# LCM32F039 register map
File version: 1.0
CPU: CM0 r1p0, little endian, MPU, no FPU, 3 interrupt priority bits
Registers are 32-bit, read-write, reset 0x0 unless marked. A register's access mark holds for its fields unless they carry their own. Offsets are from the block's base; [hi:lo] are bit positions; {n}, {i} and the like mark numbered series; 'fields as' and 'values as' point back to an identical list.

## DMAC — DMA control moudle
Base 0x48004000
{0x0+0x58*i} SAR{i} (i=0..3) — Channel {i} Source Address Register
  [31:0] SAR — Current Source Address of DMA transfer
{0x8+0x58*i} DAR{i} (i=0..3) — Channel {i} Destination Address Register
  [31:0] DAR — Current Destination address of DMA transfer
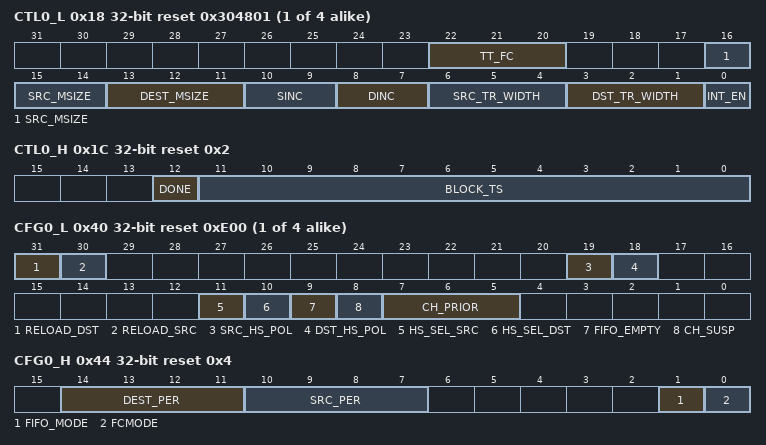
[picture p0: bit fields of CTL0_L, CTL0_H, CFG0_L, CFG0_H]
{0x18+0x58*i} CTL{i}_L reset 0x304801 (i=0..3) — Channel {i} Control Register low
  [22:20] TT_FC — Transport type and flow control
  [16:14] SRC_MSIZE — Source Burst transaction transmission length
  [13:11] DEST_MSIZE — Destination Burst Transaction Length
  [10:9] SINC — Source Address Increment
  [8:7] DINC — Destination Address Increment.
  [6:4] SRC_TR_WIDTH — Source Transfer Width
  [3:1] DST_TR_WIDTH — Destination Transfer Width
  [0] INT_EN — Interrupt Enable Bit
0x1C CTL0_H reset 0x2 — Channel 0 Source Status Register high
  [12] DONE — Done bit
  [11:0] BLOCK_TS — Block Transfer Size
{0x40+0x58*i} CFG{i}_L reset 0xE00 (i=0..3) — Channel {i} Configuration Register (low)
  [31] RELOAD_DST — Automatic Destination Reload.
  [30] RELOAD_SRC — Automatic Source Reload.
  [19] SRC_HS_POL — Source Handshaking Interface Polarity.
  [18] DST_HS_POL — Destination Handshaking Interface Polarity.
  [11] HS_SEL_SRC — Source Software or Hardware Handshaking Select.
  [10] HS_SEL_DST — Destination Software or Hardware Handshaking Select.
  [9] FIFO_EMPTY ro — Indicates if there is data left in the channel FIFO
  [8] CH_SUSP — Channel Suspend.
  [7:5] CH_PRIOR — Channel priority
0x44 CFG0_H reset 0x4 — Channel 0 Configuration Register (high)
  [14:11] DEST_PER — Assigns a hardware handshaking interface
  [10:7] SRC_PER — Assigns a hardware handshaking interface
  [1] FIFO_MODE — FIFO Mode Select.
  [0] FCMODE — Flow Control Mode
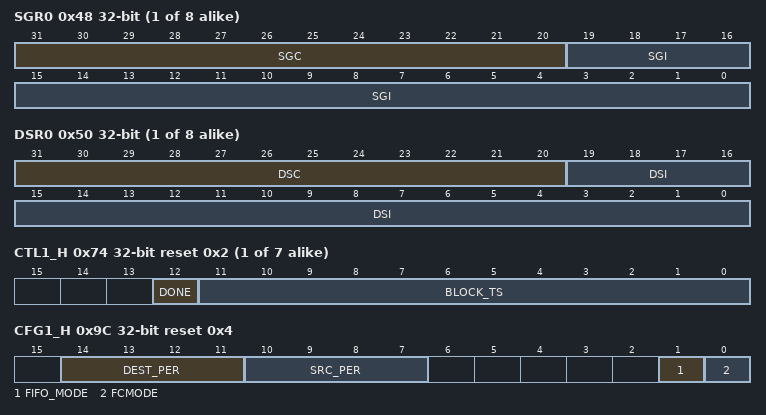
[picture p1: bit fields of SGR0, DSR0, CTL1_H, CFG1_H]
{0x48+0x58*i} SGR{i} (i=0..7) — Channel {i} Source Gather Register
  [31:20] SGC — Source gather count.
  [19:0] SGI — Source gather interval.
{0x50+0x58*i} DSR{i} (i=0..7) — Channel {i} Destination Scatter Register
  [31:20] DSC — Destination scatter count.
  [19:0] DSI — Destination scatter interval.
{0x1C+0x58*i} CTL{i}_H reset 0x2 (i=1..7) — Channel {i} Control Register high
  [12] DONE — Done bit
  [11:0] BLOCK_TS — Block Transfer Size
0x9C CFG1_H reset 0x4 — Channel 1 Configuration Register (high)
  fields as CFG0_H
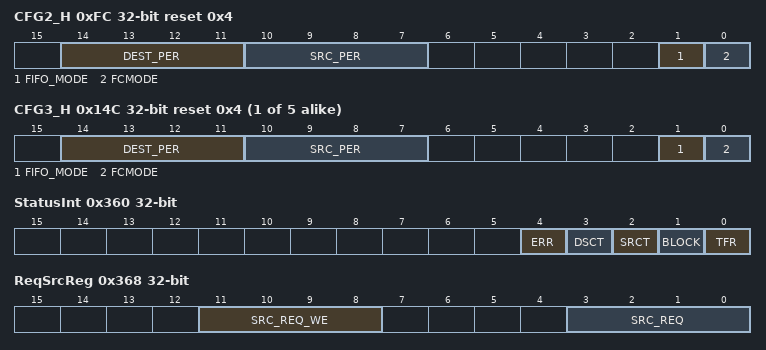
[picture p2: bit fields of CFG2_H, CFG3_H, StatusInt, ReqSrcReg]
0xFC CFG2_H reset 0x4 — Channel 2 Configuration Register (high)
  fields as CFG0_H
{0x44+0x58*i} CFG{i}_H reset 0x4 (i=3..7) — Channel {i} Configuration Register (high)
  fields as CFG0_H
0x2C0 RawTfr
  [3:0] RAWTr — Raw interrupt status
0x2C8 RawBlock
  [3:0] RAWTr — Raw interrupt status
0x2D0 RawSrcTran
  [3:0] RAWTr — Raw interrupt status
0x2D8 RawDstTran
  [3:0] RAWTr — Raw interrupt status
0x2E0 RawErr ro
  [3:0] RAWTr — Raw interrupt status
0x2E8 StatusTfr ro
  [3:0] StatusTfr — Interrupt status.
0x2F0 StatusBlock ro
  [3:0] StatusTfr — Interrupt status.
0x2F8 StatusSrcTran ro
  [3:0] StatusTfr — Interrupt status.
0x300 StatusDstTran ro
  [3:0] StatusTfr — Interrupt status.
0x308 StatusErr ro
  [3:0] StatusTfr — Interrupt status.
0x310 MaskTfr — Interrupt Mask Registers
  [15:8] INT_MASK_TFR_WE — Interrupt Mask Write Enable
0x318 MaskBlock — Interrupt Mask Registers
  [15:8] INT_MASK_TFR_WE — Interrupt Mask Write Enable
0x320 MaskSrcTran — Interrupt Mask Registers
  [15:8] INT_MASK_TFR_WE — Interrupt Mask Write Enable
0x328 MaskDstTran — Interrupt Mask Registers
  [15:8] INT_MASK_TFR_WE — Interrupt Mask Write Enable
0x330 MaskErr — Interrupt Mask Registers
  [15:8] INT_MASK_TFR_WE — Interrupt Mask Write Enable
0x338 ClearTfr wo — Interrupt Clear Registers
  [3:0] ClearTfr — Interrupt clear
0x340 ClearBlock wo — Interrupt Clear Registers
  [3:0] ClearTfr — Interrupt clear
0x348 ClearSrcTran wo — Interrupt Clear Registers
  [3:0] ClearTfr — Interrupt clear
0x350 ClearDstTran wo — Interrupt Clear Registers
  [3:0] ClearTfr — Interrupt clear
0x358 ClearErr wo — Interrupt Clear Registers
  [3:0] ClearTfr — Interrupt clear
0x360 StatusInt ro — Combined Interrupt Status Register
  [4] ERR — OR of the contents of StatusErr register.
  [3] DSCT — OR of the contents of StatusDst register.
  [2] SRCT — OR of the contents of StatusSrcTran register
  [1] BLOCK — OR of the contents of StatusBlock register.
  [0] TFR — OR of the contents of StatusTfr register
0x368 ReqSrcReg — Source Software Transaction Request Register
  [11:8] SRC_REQ_WE — Source request write enable
  [3:0] SRC_REQ — Source request
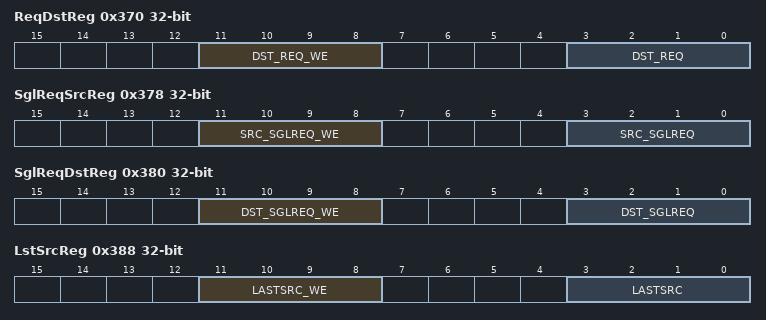
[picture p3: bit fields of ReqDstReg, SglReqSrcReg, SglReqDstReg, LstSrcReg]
0x370 ReqDstReg — Destination Software Transaction Request Register
  [11:8] DST_REQ_WE — Destination request write enable
  [3:0] DST_REQ — Destination request
0x378 SglReqSrcReg — Single Source Transaction Request Register
  [11:8] SRC_SGLREQ_WE — Single write enable
  [3:0] SRC_SGLREQ — Source single request
0x380 SglReqDstReg — Single Destination Transaction Request Register
  [11:8] DST_SGLREQ_WE — Destination write enable
  [3:0] DST_SGLREQ — Destination single or burst request
0x388 LstSrcReg — Last Source Transaction Request Register
  [11:8] LASTSRC_WE — Source last transaction request write enable
  [3:0] LASTSRC — Source last transaction request
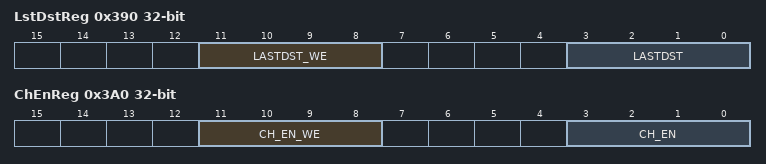
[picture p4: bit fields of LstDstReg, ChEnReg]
0x390 LstDstReg — Last Destination Transaction Request Register
  [11:8] LASTDST_WE — Destination last transaction request write enable
  [3:0] LASTDST — Destination last transaction request
0x398 DmaCfgReg — DMA Configuration Register
  [0] DMA_EN — DW_ahb_dmac Enable bit.
0x3A0 ChEnReg — DMA Channel Enable Register
  [11:8] CH_EN_WE — Channel enable write enable
  [3:0] CH_EN — Enables/Disables the channel
